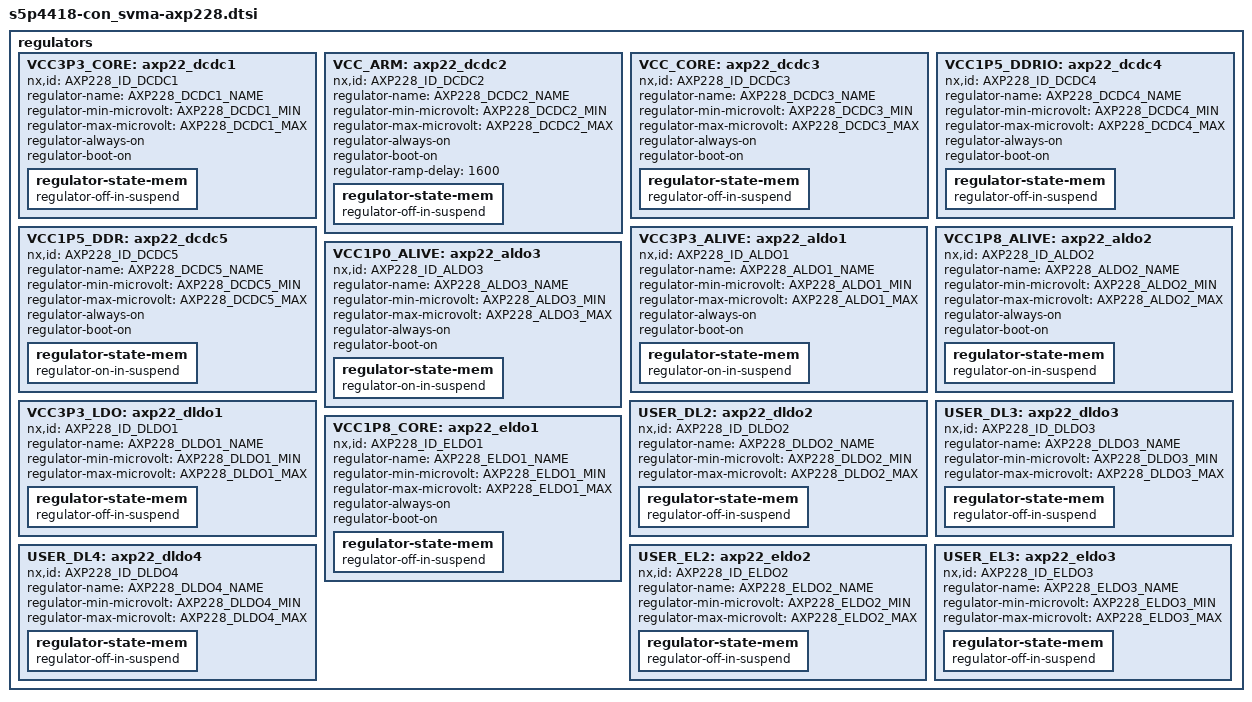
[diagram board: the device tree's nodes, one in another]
/*
 * Copyright (C) 2021 Nexell Co., Ltd.
 * Author: Jongshin Park <pjsin865@nexell.co.kr>
 *
 * This program is free software; you can redistribute it and/or
 * modify it under the terms of the GNU General Public License
 * as published by the Free Software Foundation; either version 2
 * of the License, or (at your option) any later version.
 *
 * This program is distributed in the hope that it will be useful,
 * but WITHOUT ANY WARRANTY; without even the implied warranty of
 * MERCHANTABILITY or FITNESS FOR A PARTICULAR PURPOSE.  See the
 * GNU General Public License for more details.
 *
 * You should have received a copy of the GNU General Public License
 * along with this program.  If not, see <http://www.gnu.org/licenses/>.
 */

/* DCDC-LDO ID */
#define AXP228_ID_DCDC1 0
#define AXP228_ID_DCDC2 1
#define AXP228_ID_DCDC3 2
#define AXP228_ID_DCDC4 3
#define AXP228_ID_DCDC5 4
#define AXP228_ID_RTCLDO 5
#define AXP228_ID_ALDO1 6
#define AXP228_ID_ALDO2 7
#define AXP228_ID_ALDO3 8
#define AXP228_ID_DLDO1 9
#define AXP228_ID_DLDO2 10
#define AXP228_ID_DLDO3 11
#define AXP228_ID_DLDO4 12
#define AXP228_ID_ELDO1 13
#define AXP228_ID_ELDO2 14
#define AXP228_ID_ELDO3 15
#define AXP228_ID_DC5LDO 16
#define AXP228_ID_LDOIO0 17
#define AXP228_ID_LDOIO1 18
#define AXP228_ID_SUPPLY 19
#define AXP228_ID_GPIO 20

/* DCDC and LDO Min/Max/Step Value */
#define AXP228_DCDC1_MIN 1600000 /* DCDC1 : 1600~3400, 100/setp */
#define AXP228_DCDC1_MAX 3400000
#define AXP228_DCDC1_STEP 100000
#define AXP228_DCDC2_MIN 600000 /* DCDC2 : 600~1540, 20/step */
#define AXP228_DCDC2_MAX 1540000
#define AXP228_DCDC2_STEP 20000
#define AXP228_DCDC3_MIN 600000 /* DCDC3 : 600~1860, 20/step */
#define AXP228_DCDC3_MAX 1860000
#define AXP228_DCDC3_STEP 20000
#define AXP228_DCDC4_MIN 600000 /* DCDC4 : 600~1540, 20/step */
#define AXP228_DCDC4_MAX 1540000
#define AXP228_DCDC4_STEP 20000
#define AXP228_DCDC5_MIN 1000000 /* DCDC5 : 1000~2550, 50/step */
#define AXP228_DCDC5_MAX 2550000
#define AXP228_DCDC5_STEP 50000
#define AXP228_ALDO1_MIN 700000 /* ALDO1 : 700~3300, 100/step */
#define AXP228_ALDO1_MAX 3300000
#define AXP228_ALDO1_STEP 100000
#define AXP228_ALDO2_MIN 700000 /* ALDO2 : 700~3300, 100/step */
#define AXP228_ALDO2_MAX 3300000
#define AXP228_ALDO2_STEP 100000
#define AXP228_ALDO3_MIN 700000 /* ALDO3 : 700~3300, 100/step */
#define AXP228_ALDO3_MAX 3300000
#define AXP228_ALDO3_STEP 100000
#define AXP228_DLDO1_MIN 700000 /* DLDO1 : 700~3300, 100/step */
#define AXP228_DLDO1_MAX 3300000
#define AXP228_DLDO1_STEP 100000
#define AXP228_DLDO2_MIN 700000 /* DLDO2 : 700~3300, 100/step */
#define AXP228_DLDO2_MAX 3300000
#define AXP228_DLDO2_STEP 100000
#define AXP228_DLDO3_MIN 700000 /* DLDO3 : 700~3300, 100/step */
#define AXP228_DLDO3_MAX 3300000
#define AXP228_DLDO3_STEP 100000
#define AXP228_DLDO4_MIN 700000 /* DLDO4 : 700~3300, 100/step */
#define AXP228_DLDO4_MAX 3300000
#define AXP228_DLDO4_STEP 100000
#define AXP228_ELDO1_MIN 700000 /* ELDO1 : 700~3300, 100/step */
#define AXP228_ELDO1_MAX 3300000
#define AXP228_ELDO1_STEP 100000
#define AXP228_ELDO2_MIN 700000 /* ELDO2 : 700~3300, 100/step */
#define AXP228_ELDO2_MAX 3300000
#define AXP228_ELDO2_STEP 100000
#define AXP228_ELDO3_MIN 700000 /* ELDO3 : 700~3300, 100/step */
#define AXP228_ELDO3_MAX 3300000
#define AXP228_ELDO3_STEP 100000
#define AXP228_DC5LDO_MIN 700000 /* DC5LDO : 700~1400, 100/step */
#define AXP228_DC5LDO_MAX 1400000
#define AXP228_DC5LDO_STEP 100000

/* DCDC-LDO Name */
#define AXP228_DCDC1_NAME "VCC3P3_CORE" /* dcdc1 */
#define AXP228_DCDC2_NAME "VCC_ARM" /* dcdc2 */
#define AXP228_DCDC3_NAME "VCC_CORE" /* dcdc3 */
#define AXP228_DCDC4_NAME "VCC1P5_DDRIO" /* dcdc4 */
#define AXP228_DCDC5_NAME "VCC1P5_DDR" /* dcdc5 */
#define AXP228_ALDO1_NAME "VCC3P3_ALIVE" /* aldo1 */
#define AXP228_ALDO2_NAME "VCC1P8_ALIVE" /* aldo2 */
#define AXP228_ALDO3_NAME "VCC1P0_ALIVE" /* aldo3 */
#define AXP228_DLDO1_NAME "VCC3P3_LDO" /* dldo1 */
#define AXP228_DLDO2_NAME "USER_DL2" /* dldo2 */
#define AXP228_DLDO3_NAME "USER_DL3" /* dldo3 */
#define AXP228_DLDO4_NAME "USER_DL4" /* dldo4 */
#define AXP228_ELDO1_NAME "VCC1P8_CORE" /* eldo1 */
#define AXP228_ELDO2_NAME "USER_EL2" /* eldo2 */
#define AXP228_ELDO3_NAME "USER_EL3" /* eldo3 */
#define AXP228_DC5LDO_NAME "VCC1P0_CORE" /* dc5ldo */

regulators {
	VCC3P3_CORE:axp22_dcdc1 {
			nx,id = <AXP228_ID_DCDC1>;
			regulator-name = AXP228_DCDC1_NAME;
			regulator-min-microvolt = <AXP228_DCDC1_MIN>;
			regulator-max-microvolt = <AXP228_DCDC1_MAX>;
			regulator-always-on;
			regulator-boot-on;
			regulator-state-mem {
				regulator-off-in-suspend;
			};
		};

	VCC_ARM:axp22_dcdc2 {
			nx,id = <AXP228_ID_DCDC2>;
			regulator-name = AXP228_DCDC2_NAME;
			regulator-min-microvolt = <AXP228_DCDC2_MIN>;
			regulator-max-microvolt = <AXP228_DCDC2_MAX>;
			regulator-always-on;
			regulator-boot-on;
			regulator-ramp-delay = <1600>;
			regulator-state-mem {
				regulator-off-in-suspend;
			};
		};

	VCC_CORE:axp22_dcdc3 {
			nx,id = <AXP228_ID_DCDC3>;
			regulator-name = AXP228_DCDC3_NAME;
			regulator-min-microvolt = <AXP228_DCDC3_MIN>;
			regulator-max-microvolt = <AXP228_DCDC3_MAX>;
			regulator-always-on;
			regulator-boot-on;
			regulator-state-mem {
				regulator-off-in-suspend;
			};
		};

	VCC1P5_DDRIO:axp22_dcdc4 {
			nx,id = <AXP228_ID_DCDC4>;
			regulator-name = AXP228_DCDC4_NAME;
			regulator-min-microvolt = <AXP228_DCDC4_MIN>;
			regulator-max-microvolt = <AXP228_DCDC4_MAX>;
			regulator-always-on;
			regulator-boot-on;
			regulator-state-mem {
				regulator-off-in-suspend;
			};
		};

	VCC1P5_DDR:axp22_dcdc5 {
			nx,id = <AXP228_ID_DCDC5>;
			regulator-name = AXP228_DCDC5_NAME;
			regulator-min-microvolt = <AXP228_DCDC5_MIN>;
			regulator-max-microvolt = <AXP228_DCDC5_MAX>;
			regulator-always-on;
			regulator-boot-on;
			regulator-state-mem {
				regulator-on-in-suspend;
			};
		};

	VCC3P3_ALIVE:axp22_aldo1 {
			nx,id = <AXP228_ID_ALDO1>;
			regulator-name = AXP228_ALDO1_NAME;
			regulator-min-microvolt = <AXP228_ALDO1_MIN>;
			regulator-max-microvolt = <AXP228_ALDO1_MAX>;
			regulator-always-on;
			regulator-boot-on;
			regulator-state-mem {
				regulator-on-in-suspend;
			};
		};

	VCC1P8_ALIVE:axp22_aldo2 {
			nx,id = <AXP228_ID_ALDO2>;
			regulator-name = AXP228_ALDO2_NAME;
			regulator-min-microvolt = <AXP228_ALDO2_MIN>;
			regulator-max-microvolt = <AXP228_ALDO2_MAX>;
			regulator-always-on;
			regulator-boot-on;
			regulator-state-mem {
				regulator-on-in-suspend;
			};
		};

	VCC1P0_ALIVE:axp22_aldo3 {
			nx,id = <AXP228_ID_ALDO3>;
			regulator-name = AXP228_ALDO3_NAME;
			regulator-min-microvolt = <AXP228_ALDO3_MIN>;
			regulator-max-microvolt = <AXP228_ALDO3_MAX>;
			regulator-always-on;
			regulator-boot-on;
			regulator-state-mem {
				regulator-on-in-suspend;
			};
		};

	VCC3P3_LDO:axp22_dldo1 {
			nx,id = <AXP228_ID_DLDO1>;
			regulator-name = AXP228_DLDO1_NAME;
			regulator-min-microvolt = <AXP228_DLDO1_MIN>;
			regulator-max-microvolt = <AXP228_DLDO1_MAX>;
			regulator-state-mem {
				regulator-off-in-suspend;
			};
		};

	USER_DL2:axp22_dldo2 {
			nx,id = <AXP228_ID_DLDO2>;
			regulator-name = AXP228_DLDO2_NAME;
			regulator-min-microvolt = <AXP228_DLDO2_MIN>;
			regulator-max-microvolt = <AXP228_DLDO2_MAX>;
			regulator-state-mem {
				regulator-off-in-suspend;
			};
		};

	USER_DL3:axp22_dldo3 {
			nx,id = <AXP228_ID_DLDO3>;
			regulator-name = AXP228_DLDO3_NAME;
			regulator-min-microvolt = <AXP228_DLDO3_MIN>;
			regulator-max-microvolt = <AXP228_DLDO3_MAX>;
			regulator-state-mem {
				regulator-off-in-suspend;
			};
		};

	USER_DL4:axp22_dldo4 {
			nx,id = <AXP228_ID_DLDO4>;
			regulator-name = AXP228_DLDO4_NAME;
			regulator-min-microvolt = <AXP228_DLDO4_MIN>;
			regulator-max-microvolt = <AXP228_DLDO4_MAX>;
			regulator-state-mem {
				regulator-off-in-suspend;
			};
		};

	VCC1P8_CORE:axp22_eldo1 {
			nx,id = <AXP228_ID_ELDO1>;
			regulator-name = AXP228_ELDO1_NAME;
			regulator-min-microvolt = <AXP228_ELDO1_MIN>;
			regulator-max-microvolt = <AXP228_ELDO1_MAX>;
			regulator-always-on;
			regulator-boot-on;
			regulator-state-mem {
				regulator-off-in-suspend;
			};
		};

	USER_EL2:axp22_eldo2 {
			nx,id = <AXP228_ID_ELDO2>;
			regulator-name = AXP228_ELDO2_NAME;
			regulator-min-microvolt = <AXP228_ELDO2_MIN>;
			regulator-max-microvolt = <AXP228_ELDO2_MAX>;
			regulator-state-mem {
				regulator-off-in-suspend;
			};
		};

	USER_EL3:axp22_eldo3 {
			nx,id = <AXP228_ID_ELDO3>;
			regulator-name = AXP228_ELDO3_NAME;
			regulator-min-microvolt = <AXP228_ELDO3_MIN>;
			regulator-max-microvolt = <AXP228_ELDO3_MAX>;
			regulator-state-mem {
				regulator-off-in-suspend;
			};
		};
}; /* regulators */
